VERSION ""

NS_ :

BS_:

BU_: Tester Charger TEL Display BMS VCU MotorController Front_BPS Rear_BPS
VAL_TABLE_ Brightness_Control 10 "100% Brightness" 9 "90% Brightness" 8 "80% Brightness" 7 "70% Brightness" 6 "60% Brightness" 5 "50% Brightness" 4 "40% Brightness" 3 "30% Brightness" 2 "20% Brightness" 1 "10% Brightness" 0 "100% Brightness" ;
VAL_TABLE_ VCU_Charge_Current_Lim_A 7 "FAULT_BIT_READ_SBS_CONFIG" 6 "FAULT_BIT_READ_CALIBRATION" 5 "FAULT_BIT_READ_POWER" 4 "FAULT_BIT_READ_FUEL_GAUGING" 3 "FAULT_BIT_READ_ADV_CHRG_ALGO" 2 "FAULT_BIT_READ_PERM_FAIL" 1 "FAULT_BIT_READ_SETTINGS" 0 "FAULT_BIT_READ_PROTECTION" ;
VAL_TABLE_ Hibernation 2 "Blink" 1 "Enabled" 0 "Disabled" ;
VAL_TABLE_ SpeedMode 3 "Rush" 2 "Ride" 1 "Eco" 0 "Default" ;
VAL_TABLE_ TripStatus 1 "Trip2" 0 "Trip1" ;
VAL_TABLE_ Charger_Status_ERR_NRML 1 "Error" 0 "Normal" ;
VAL_TABLE_ Charger_TX 1 "Disable" 0 "Enable" ;
VAL_TABLE_ Error_State 2 "Permanenet_Fault" 1 "Temporary_Fault" 0 "No Fault" ;
VAL_TABLE_ Kill_SwitchStatus 1 "kill Switch Off" 0 "Kill Switch On" ;
VAL_TABLE_ Switch_statius 1 "Pressed" 0 "Not  Pressed" ;
VAL_TABLE_ Throttle_Control 1 "VCU CAN Command throttle%" 0 "Motor Controller HW Throttle%" ;
VAL_TABLE_ DriveMode_Req 3 "Rush" 2 "Ride" 1 "Eco" 0 "Default" 7 "Reserved" 6 "Reserved" 5 "Reserved" 4 "Reserved" ;
VAL_TABLE_ Deratings 1 "Enabled" 0 "Disabled" ;
VAL_TABLE_ DriveMode_Ack 7 "Reserved" 6 "Reserved" 5 "Reserved" 4 "Reserved" 3 "Rush" 2 "Ride" 1 "Eco" 0 "Reserved" ;
VAL_TABLE_ OCD_Latch 1 "Lacth" 0 "Default" ;
VAL_TABLE_ Load_V_present 1 "DFET On" 0 "DFET Off" ;
VAL_TABLE_ KeyStatus_BMS 1 "Connected" 0 "Not Connected" ;
VAL_TABLE_ DFET_Status 1 "MDFET_ON" 0 "MDFET_OFF" ;
VAL_TABLE_ BMS_Fault_Status 1 "Error" 0 "Normal" ;
VAL_TABLE_ Battery_DFET_Temp_Warning 2 "FET_UNDER_TEMP" 1 "FET_OVER_TEMP" 0 "NO_FET_TEMP_FAULT" ;
VAL_TABLE_ Battery_DFET_TempFault 3 "Reserved" 2 "DFET Under Temperature" 1 "DFET Over Temperature" 0 "No Fault" ;
VAL_TABLE_ Battery_CFET_Temp_Fault 3 "Reserved" 2 "CFET Uder Temperature" 1 "CFET Over Temperature" 0 "No Fault" ;
VAL_TABLE_ CellVoltageFault 3 "Reserved" 2 "Cell Under Votage Fault" 1 "Cell Over Voltage Fault" 0 "No Fault" ;
VAL_TABLE_ Battery_Voltage_fault 3 "Reserved" 2 "Pack Under Voltage Fault" 1 "Pack Over Voltage Fault" 0 "No Fault" ;
VAL_TABLE_ Battery_Thermalrunaway_fault 1 "Fault" 0 "No Fault" ;
VAL_TABLE_ Battery_DischargeTempFault 4 "Charging Under Temperature" 3 "Discharging Under Temperature" 2 "Charging Over Temperature" 1 "Discharging Over Temperature" 0 "No Fault" ;
VAL_TABLE_ Reverse_Enable_Disable 1 "Disable" 0 "Enable" ;
VAL_TABLE_ Charger_LED_Color 3 "Reserved" 2 "Green" 1 "Red" 0 "Disable" ;
VAL_TABLE_ ChargerLEDBlink 15 "na" 14 "na" 13 "na" 12 "na" 11 "na" 10 "na" 9 "na" 8 "na" 7 "na" 6 "na" 5 "na" 4 "blink 4 times" 3 "blink 3 times" 2 "blink 2 times" 1 "blink 1 time" 0 "no blink" ;
VAL_TABLE_ SOH_estimation_flag 7 "NA" 6 "NA" 5 "NA" 4 "NA" 3 "Both flag on" 2 "SOH estimation flag on" 1 "SOH reset trigger on" 0 "Default" ;
VAL_TABLE_ Cell_Upnormal_Voltage 2 "UP_Normal_Min_Voltage_Fault" 1 "UP_Normal_Max_Voltage_Fault" 0 "NO_error" ;
VAL_TABLE_ BMS_State 6 "BMS_Calibration" 5 "BMS_Critical_Fault" 4 "BMS_Charging_Fault" 3 "BMS_Discharging_Fault" 2 "BMS_Charging" 1 "BMS_Discharging" 0 "Idle" ;
VAL_TABLE_ VCU_Trip_status 1 "Trip 2" 0 "Trip 1" ;
VAL_TABLE_ Rare_BPS_Timeout 1 "Rare_BPS_Timeout" 0 "No error" ;
VAL_TABLE_ Front_BPS_TimeOut 2 "reserved" 1 "Front_BPS_Timeout" 0 "No_error" ;
VAL_TABLE_ VehicleModeStatus 6 "Traction disable" 5 "Linphome mode while traction" 4 "Charge" 3 "Traction" 2 "Idle" 1 "Authentication" 0 "Lock" ;
VAL_TABLE_ BootStatus 1 "Boot_opean" 0 "Boot_locked" ;
VAL_TABLE_ ECUErrorCode 326 "Cell Under Voltage Fault" 325 "Cell Over Voltage Fault" 322 "BrakeLamp_Fault" 318 "BMS_CANMSG_Timeout" 315 "Battery_Thermal_Runaway_Fault" 314 "BatteryDisSortCircuitFault" 312 "Charging_under_temp" 310 "Discharging_under_temp" 309 " Charging_over_current_fault" 308 "Discharging_over_current_fault" 307 "Charging_over_temp" 306 "Discharging_over_temp" 305 "DFET under temperature" 304 "DFET over temperature" 303 "CFET under temperature" 302 "CFET over temperature" 301 "Fuse_Fault" 203 "BMS_SCD" 142 "Throttle_2_Low_Voltage" 140 "Motor_Control_Error" 139 "Application_parameters_Fault" 137 "Kill_switch_SRO" 136 "Max_speed_exceeded" 135 "Controller_logic_supply_error" 134 "Throttle channel mismatch " 133 "Motor Stalled" 132 "Throttle SRO" 131 "Contactor_Coil_Overcurrent" 130 "Parameter_Limitation" 129 "Throttle_2_High_Voltage" 128 "High Motor Temperature" 127 "High Controller Temperature" 126 "Corrupted_Position_Sensor_Cal" 125 "Corrupted_Persis_Para" 124 "Corrupted_Comm_Parameters" 123 "Corrupted_Throttle_Calibration" 122 "Corrupted V&I Sensor Calibration" 121 "Motor_Temperature_Sensor" 120 "Controller_Temperature_Sensor" 119 "Motor over temperature" 118 "Controller over temperature" 117 "Charging_Of_Capacitors_Failed" 116 "Throttle 1 Low Voltage" 115 "Throttle 1 High Voltage" 114 "Encoder_Fault" 113 "Throttle_Pedal_Cal_Error" 112 "Corrupted_Application_Parameters" 111 "Contactor_Welded" 110 "Contactor_Bridge_Fault" 109 "Over_Current" 108 "Current_Sensor_Fault" 107 "Sensor_Calibration_Error_V&I" 106 "12V_Failure" 105 "5V_Failure" 104 "Under_Voltage" 103 "Over_Voltage" 102 "Low_Battery_Voltage" 101 "High_Battery_Voltage" ;
VAL_TABLE_ SolenoidFeedbackStatus 1 "solenoid latched" 0 "solenoid unlatched" ;
VAL_TABLE_ RegenFlag 1 "Enable" 0 "Disable" ;
VAL_TABLE_ CalibrationDataSetNumber 4 "Cell 13,14 data" 3 "Cell 10,11,12 data" 2 "Cell 7,8,9 data" 1 "Cell 4,5,6 data" 0 "Cell 1,2,3 data" ;
VAL_TABLE_ CalibrationDescription 171 "Current Mode" 170 "Voltage Mode  " 34 "Current Calibration Third Point" 33 "Voltage Calibration Third Point" 18 "Current Calibration Second Point" 17 "Voltage Calibration Second Point" 2 "Current Calibration First Point" 1 "Voltage Calibration First Point" ;
VAL_TABLE_ CalibrationAckStatus 171 "Current Mode" 170 "Voltage Mode" 17 "Second Voltage point read" 3 "FinalCurrentPointReadCalibrated" 2 "Current point read" 1 "First Voltage point read" ;
VAL_TABLE_ AFESrecWriteStatus 1 "afe_srec written" 0 "afe_srec_not_written" ;
VAL_TABLE_ AFEDataFlashMemoryWriteFaultCode 7 " FAULT_BIT_READ_SBS_CONFIG" 6 "FAULT_BIT_READ_CALIBRATION" 5 "FAULT_BIT_READ_POWER" 4 "FAULT_BIT_READ_FUEL_GAUGING" 3 " FAULT_BIT_READ_ADV_CHRG_ALGO" 2 "FAULT_BIT_READ_PERM_FAIL" 1 "FAULT_BIT_READ_SETTINGS" 0 "FAULT_BIT_READ_PROTECTION" ;
VAL_TABLE_ I2c_Status 517 "STATUS_I2C_BUS_BUSY" 516 "STATUS_I2C_ABORTED" 515 "STATUS_I2C_ARBITRATION_LOST " 514 "STATUS_I2C_RX_OVERRUN " 513 "STATUS_I2C_TX_UNDERRUN" 512 "STATUS_I2C_RECEIVED_NACK " ;
VAL_TABLE_ SystemDiagInitFaultCode 30 "FaultBitReadAFEHistoryFaultData" 29 "FAULTBIT_READ_AFE_LIFE_TIME_DATA" 28 "FAULT_BIT_INT_FLASH_WRITE_FAILED" 27 "FAULT_BIT_INT_FLASH_READ_FAILED" 26 "AULT_BIT_ADC_READ" 25 "FAULT_BIT_AFE_READ " 24 "FAULT_BIT_POST_OS_INIT_FAILED" 23 "FAULT_BIT_OS_CREATE_INTRPTS" 22 "FAULT_BIT_OS_CREATE_TASK" 21 "FAULT_BIT_OS_CREATE_QUEUE" 20 "FAULT_BIT_OS_CREATE_SEMPR" 19 "FAULT_BIT_CAN_TX" 18 "FAULT_BIT_INTERNAL_FLASH_INIT" 17 "FAULT_BIT_I2C_CRC_ERROR" 16 "FAULT_BIT_I2C_RX_ERROR" 15 "FAULT_BIT_I2C_TX_ERROR" 14 "FAULT_BIT_I2C_INIT" 13 "FAULT_BIT_ADC_INIT" 12 "FAULT_BIT_TIMER_FTM1" 11 "FAULT_BIT_TIMER_FTM0" 10 "FAULT_BIT_CAN_INIT_1" 9 "FAULT_BIT_GPIO_INIT" 8 "FAULT_BIT_CLOCK_UPDATE" 7 "FAULT_BIT_BOOT_CLOCK_INIT" 6 "FAULT_BIT_RESET_SOFT" 5 "FAULT_BIT_RESET_NRST_EXT" 4 "FAULT_BIT_RESET_ACK_ERR" 3 "FAULT_BIT_RESET_LV_DETECT" 2 "FAULT_BIT_RESET_SJTAG" 1 "FAULT_BIT_RESET_POWER_ON" 0 "FAULT_BIT_RESET_WDG" ;
VAL_TABLE_ BatteryAFETempWarning 4 "CHARGING_UNDER_TEMP_FAULT" 3 "DISCHARGING_UNDER_TEMPE_FAULT" 2 "CHARGING_OVER_TEMP_FAULT" 1 "DISCHARGING_OVER_TEMPE_FAULT" 0 "NO_TEMP_FAULT" ;
VAL_TABLE_ BatteryMDFETTempWarning 2 "FET_UNDER_TEMP" 1 "FET_OVER_TEMP" 0 "NO_FET_TEMP_FAULT" ;
VAL_TABLE_ BatteryCellVoltageWarning 2 "UNDER_VOLTAGE_FAULT" 1 "OVER_VOLTAGE_FAULT" 0 "NO_VOLTAGE_FAULT" ;
VAL_TABLE_ BatteryCFETTempWarning 2 "CHARG_UNDER_TEMP_FAULT" 1 "CHARG_OVER_TEMP_FAULT" 0 "NO_CHG_TEMP_FAULT" ;
VAL_TABLE_ BatteryTempWarning 4 "CHARGING_UNDER_TEMP_FAULT" 3 "DISCHARGING_UNDER_TEMPE_FAULT" 2 "CHARGING_OVER_TEMP_FAULT" 1 "DISCHARGING_OVER_TEMPE_FAULT" 0 "NO_TEMP_FAULT" ;
VAL_TABLE_ BatteryCurrentWarning 3 "RESERVED" 2 " CHARGING_OVER_CURRENT_FAULT" 1 "DISCHARGING_OVER_CURRENT_FAULT" 0 "NO_CURRENT_FAULT" ;
VAL_TABLE_ ParkArrowBlink 3 "Top and Bottom Arrow Blink" 2 "Top Arrow Blink" 1 "Bottom Arrow Blink" 0 "No Blink" ;
VAL_TABLE_ On_Off 1 "ON" 0 "OFF" ;
VAL_TABLE_ LED_Color 3 "Reserved" 2 "Green" 1 "Red" 0 "Disable" ;
VAL_TABLE_ BatteryChargingTempFault 4 "Reserved" 3 "Reserved" 2 "Charging Under Temperature" 1 "Charging Over Temperature" 0 "No Fault" ;
VAL_TABLE_ BatteryFull 1 "Battery Full" 0 "Default" ;
VAL_TABLE_ Latch 1 "Latch" 0 "Default" ;
VAL_TABLE_ Gauge_TemperatureFault 3 "Reserved" 2 "Gauge UT Fault" 1 "Gauge OT Fault" 0 "Gauge Temperature Normal" ;
VAL_TABLE_ Auth_Fault 1 "Auth Fault" 0 "No Auth Fault" ;
VAL_TABLE_ Fuse 1 "Fuse Blown" 0 "Normal" ;
VAL_TABLE_ Reset_Display 7 "Reserved" 6 "Reserved" 5 "Reserved" 4 "Reserved" 3 "Clear Service Icon" 2 "Reset Trip 2" 1 "Reset Trip1" 0 "Default" ;
VAL_TABLE_ CFET_Status 1 "CFET On" 0 "CFET Off" ;
VAL_TABLE_ Charger_Enable 1 "Disable" 0 "Enable" ;
VAL_TABLE_ DrivenMode 7 "Reserved" 6 "Reserved" 5 "Reserved" 4 "Reserved" 3 "Reserved" 2 "Rush" 1 "Sport" 0 "Ride" ;
VAL_TABLE_ Park_Mode_Direction 1 "Forward" 0 "Reverse" ;
VAL_TABLE_ Park_Mode_Enable 1 "Park Enabled" 0 "Park Disabled" ;
VAL_TABLE_ Version_Req 1 "Update Version" 0 "Default" ;
VAL_TABLE_ VehicleMode 9 "Reserved" 8 "Reserved" 7 "Reserved" 6 "Hibernation" 5 "Cloud Update Mode" 4 "Charging" 3 "Reverse" 2 "Forward" 1 "Idle" 0 "Sleep/Lock" ;
VAL_TABLE_ FET_Fault 3 "Reserved" 2 "Reserved" 1 "Over Temperature " 0 "No Fault" ;
VAL_TABLE_ Precharging_Status 3 "Precharging Failed" 2 "Precharging Successful" 1 "Precharging In-progress" 0 "Default" ;
VAL_TABLE_ Drive_Manoeuvre 4 "Acceleration Backward" 3 "Direction Transition" 2 "Service Braking " 1 "Neutral braking" 0 "Accelartion Forward  " ;
VAL_TABLE_ Motor_ErrorCodes 94 "Kill switch Off" 93 "Kill switch SRO" 83 "Motor stalled " 82 "Throttle SRO" 52 "High motor temperature " 51 "High controller temperature " 97 "Motor control error " 96 "Application parameters fault" 92 "Max. speed exceeded " 90 "Controller logicsupply error " 85 "Throttle channel mismatch " 66 "Contactor coil overcurrent" 56 "Parameter limitation" 54 "Throttle 2 Low Voltage" 53 "Throttle 2 High Voltage" 49 "Corrupted positionsensor cal" 48 "Corrupted Persis Para" 47 "Corrupted Comm parameters \r" 46 "Corrupted throttle calibration" 45 "Corrupted V&I sensor calibration" 44 "Motor temperature sensor" 43 "Controller temperature sensor" 42 "Motor over temperature" 36 "Charging of capacitors failed " 34 "Throttle 1 Low Voltage" 32 "Encoder Fault" 41 "Controller over temperature" 33 "Throttle 1 High Voltage" 31 "Throttle Pedal Cal Error" 26 "Corrupted Application Parameters" 25 "Contactor  Welded" 24 "Contactor Bridge Fault" 21 "Over Current" 18 "Current Sensor Fault" 17 "Sensor Calibration Error V&I" 16 "12V Failure" 15 "5V Failure" 14 "Under Voltage V<32" 13 "Over Voltage V>62" 12 "Low Battery Voltage V<28" 11 "High Battery Voltage V>100" ;
VAL_TABLE_ Am_Pm 1 "pm" 0 "am" ;
VAL_TABLE_ Blink 1 "Blinking" 0 "No Blinking" ;
VAL_TABLE_ Trip 1 "Trip 2" 0 "Trip 1" ;
VAL_TABLE_ Enable_Disable 1 "Enabled" 0 "Disabled" ;
VAL_TABLE_ Direction 3 "Reserved" 2 "Reverse" 1 "Forward" 0 "Neutral" ;
VAL_TABLE_ KillSwitch 1 "Kill Switch Off" 0 "Kill Switch On" ;
VAL_TABLE_ PowerStage 3 "Not Used" 2 "On" 1 "Active Short" 0 "Off" ;
VAL_TABLE_ MotorMode 7 "Reserved" 6 "Reserved" 5 "Reserved" 4 "Reserved" 3 "Rush" 2 "Ride" 1 "Eco" 0 "Reserved" ;
VAL_TABLE_ BrakeStatus 1 "Pressed" 0 "Not Pressed" ;
VAL_TABLE_ SideStandStatus 1 "Up" 0 "Down" ;
VAL_TABLE_ ServiceIndication 1 "Enable" 0 "Disable" ;
VAL_TABLE_ ChargePlugStatus 1 "Connected" 0 "Not Connected" ;
VAL_TABLE_ RegenStatus 1 "Enabled" 0 "Disabled" ;
VAL_TABLE_ VCU_DisplayMode 9 "Reserved" 8 "Reserved" 7 "Reserved" 6 "Factory Mode" 5 "Charging" 4 "Park Forward" 3 "Park Reverse" 2 "Forward" 1 "Idle" 0 "Sleep" ;
VAL_TABLE_ Green_Red 3 "Green&Red" 2 "Red" 1 "Green" 0 "Default" ;
VAL_TABLE_ CurrentFaults 3 "Reserved" 2 "Charging Over Current Fault" 1 "Discharging Over Current Fault" 0 "No Fault" ;
VAL_TABLE_ VoltageFaults 3 "Reserved " 2 "Under Voltage Fault" 1 "Over Voltage Fault" 0 "No Fault" ;
VAL_TABLE_ BatteryDischargingTempFault 4 "Reserved" 3 "Reserved" 2 "Discharging Under Temperature" 1 "Discharging Over Temperature" 0 "No Fault" ;
VAL_TABLE_ Fault 1 "Fault" 0 "No Fault" ;
VAL_TABLE_ Authentication 3 "Fail" 2 "Pass" 1 "InProgress" 0 "Default" ;
VAL_TABLE_ BalancingStatus 1 "Balancing" 0 "Not Balancing" ;
VAL_TABLE_ BMS_Status 10 "Reserved" 9 "Reserved" 8 "Reserved" 7 "Charge Recovery Fault" 6 "Discharge Recovery Fault" 5 "Critical Fault" 4 "Hibernate" 3 "Charging" 2 "Discharging" 1 "Precharging" 0 "Sleep" ;
VAL_TABLE_ charger_status_msg 1 "Error" 0 "Normal" ;
VAL_TABLE_ SECURITY_Mode_OP_sts 3 "Sealed" 2 "Unsealed" 1 "Full_Access" 0 "Reserved" ;
VAL_TABLE_ Error_Code_BT_Sts 7 "Unknown_Error" 6 "Bad_Size" 5 "Overflow/UnderFlow" 4 "AccessDenied" 3 "unsupported_Command" 2 "Reserved_Command" 1 "Busy" 0 "OK" ;

BO_ 3221225472 VECTOR__INDEPENDENT_SIG_MSG: 0 Vector__XXX
 SG_ subversion_u8 : 0|8@1+ (1,0) [0|255] "" Vector__XXX

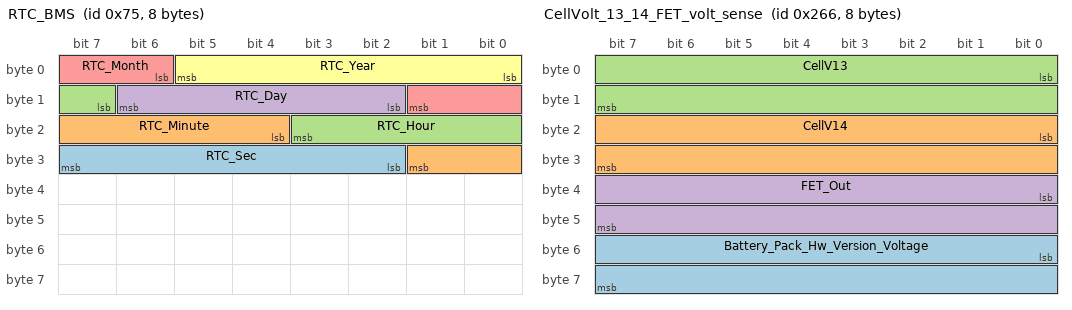
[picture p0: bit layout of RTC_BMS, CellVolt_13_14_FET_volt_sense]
BO_ 117 RTC_BMS: 8 BMS
 SG_ RTC_Sec : 26|6@1+ (1,0) [0|63] ""  VCU
 SG_ RTC_Minute : 20|6@1+ (1,0) [0|63] ""  VCU
 SG_ RTC_Hour : 15|5@1+ (1,0) [0|31] ""  VCU
 SG_ RTC_Day : 10|5@1+ (1,0) [0|31] ""  VCU
 SG_ RTC_Month : 6|4@1+ (1,0) [0|15] ""  VCU
 SG_ RTC_Year : 0|6@1+ (1,0) [0|63] ""  VCU

BO_ 614 CellVolt_13_14_FET_volt_sense: 8 BMS
 SG_ Battery_Pack_Hw_Version_Voltage : 48|16@1+ (0.01,0) [0|655.35] "" Vector__XXX
 SG_ CellV14 : 16|16@1+ (0.001,0) [0|655.35] "V" Vector__XXX
 SG_ CellV13 : 0|16@1+ (0.001,0) [0|65.535] "V" Vector__XXX
 SG_ FET_Out : 32|16@1+ (0.01,0) [0|65.535] "V"  VCU,TEL

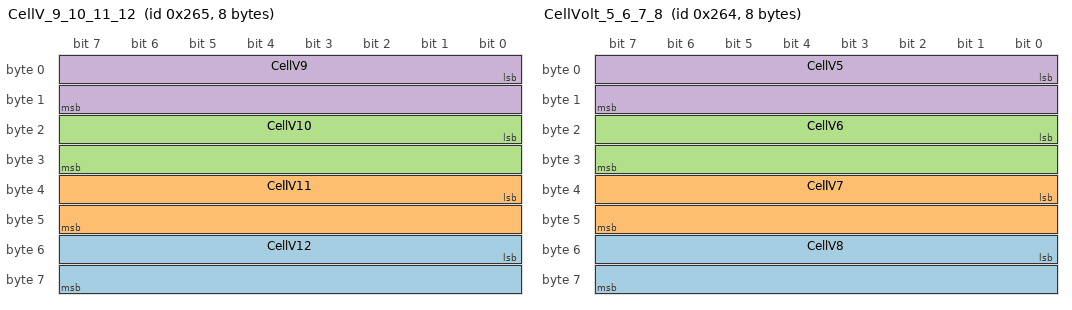
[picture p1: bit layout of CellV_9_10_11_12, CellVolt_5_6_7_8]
BO_ 613 CellV_9_10_11_12: 8 BMS
 SG_ CellV12 : 48|16@1+ (0.001,0) [0|65.535] ""  VCU,TEL
 SG_ CellV11 : 32|16@1+ (0.001,0) [0|65.535] ""  VCU,TEL
 SG_ CellV10 : 16|16@1+ (0.001,0) [0|65.535] ""  VCU,TEL
 SG_ CellV9 : 0|16@1+ (0.001,0) [0|65.535] ""  VCU,TEL

BO_ 612 CellVolt_5_6_7_8: 8 BMS
 SG_ CellV8 : 48|16@1+ (0.001,0) [0|65.535] ""  VCU,TEL
 SG_ CellV7 : 32|16@1+ (0.001,0) [0|65.535] "V"  VCU,TEL
 SG_ CellV6 : 16|16@1+ (0.001,0) [0|65.535] ""  VCU,TEL
 SG_ CellV5 : 0|16@1+ (0.001,0) [0|65.535] ""  VCU,TEL

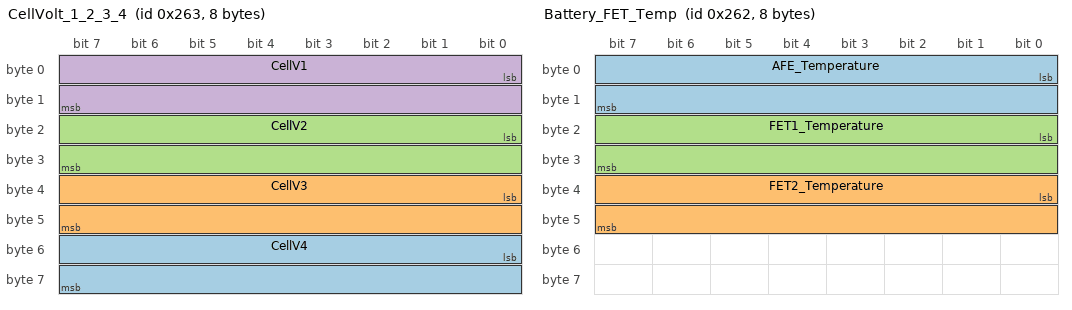
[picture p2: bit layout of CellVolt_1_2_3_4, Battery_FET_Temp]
BO_ 611 CellVolt_1_2_3_4: 8 BMS
 SG_ CellV4 : 48|16@1+ (0.001,0) [0|65.535] ""  VCU,TEL
 SG_ CellV3 : 32|16@1+ (0.001,0) [0|65.535] ""  VCU,TEL
 SG_ CellV2 : 16|16@1+ (0.001,0) [0|65.535] ""  VCU,TEL
 SG_ CellV1 : 0|16@1+ (0.001,0) [0|65.535] "V"  VCU,TEL

BO_ 610 Battery_FET_Temp: 8 BMS
 SG_ AFE_Temperature : 0|16@1- (0.1,0) [-327.68|327.67] "" Vector__XXX
 SG_ FET2_Temperature : 32|16@1- (0.01,0) [-327.68|327.67] "degC"  VCU,TEL
 SG_ FET1_Temperature : 16|16@1- (0.01,0) [-327.68|327.67] "degC"  VCU,TEL

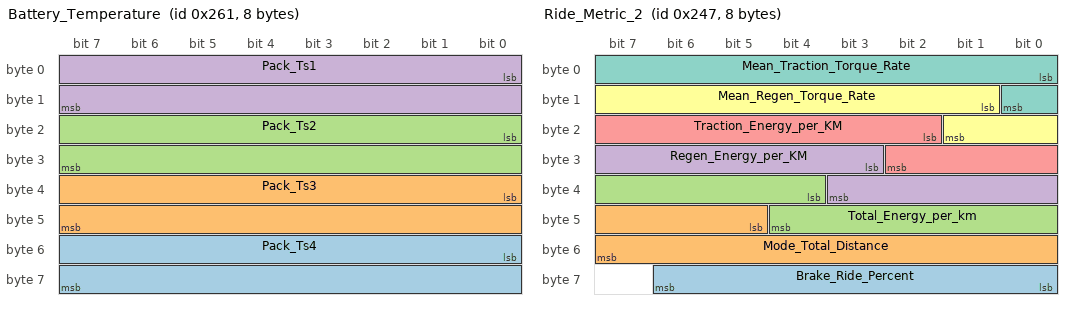
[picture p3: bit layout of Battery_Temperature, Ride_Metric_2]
BO_ 609 Battery_Temperature: 8 BMS
 SG_ Pack_Ts4 : 48|16@1- (0.01,0) [-327.68|327.67] "degC"  VCU,TEL
 SG_ Pack_Ts3 : 32|16@1- (0.01,0) [-327.68|327.67] "degC"  VCU,TEL
 SG_ Pack_Ts2 : 16|16@1- (0.01,0) [-3276.8|3276.7] "degC"  VCU,TEL
 SG_ Pack_Ts1 : 0|16@1- (0.01,0) [-327.68|327.67] "degC"  VCU,TEL

BO_ 583 Ride_Metric_2: 8 VCU
 SG_ Brake_Ride_Percent : 56|7@1+ (1,0) [0|127] ""  TEL
 SG_ Mode_Total_Distance : 45|11@1+ (0.1,0) [0|204.7] ""  TEL
 SG_ Total_Energy_per_km : 36|9@1+ (0.1,0) [0|51.1] ""  TEL
 SG_ Regen_Energy_per_KM : 27|9@1+ (0.1,0) [0|51.1] ""  TEL
 SG_ Traction_Energy_per_KM : 18|9@1+ (0.1,0) [0|51.1] ""  TEL
 SG_ Mean_Regen_Torque_Rate : 9|9@1+ (1,0) [0|511] ""  TEL
 SG_ Mean_Traction_Torque_Rate : 0|9@1+ (1,0) [0|511] ""  TEL

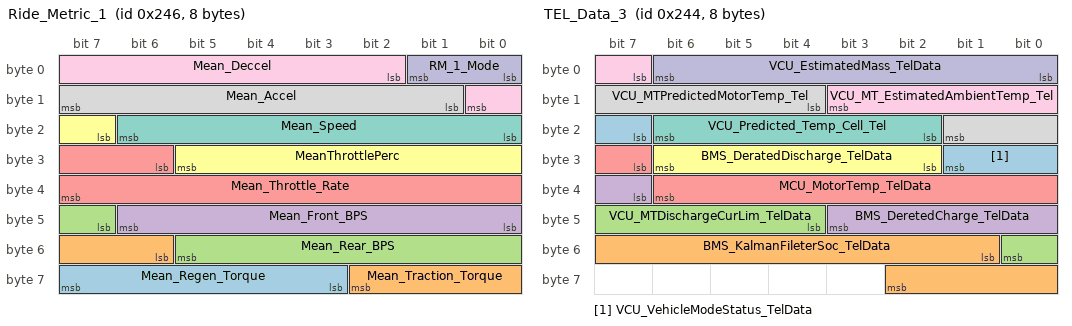
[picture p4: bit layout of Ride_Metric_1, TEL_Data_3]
BO_ 582 Ride_Metric_1: 8 VCU
 SG_ Mean_Regen_Torque : 59|5@1+ (1,0) [0|31] ""  TEL
 SG_ Mean_Traction_Torque : 54|5@1+ (1,0) [0|31] ""  TEL
 SG_ Mean_Rear_BPS : 47|7@1+ (1,0) [0|127] ""  TEL
 SG_ Mean_Front_BPS : 40|7@1+ (1,0) [0|127] ""  TEL
 SG_ Mean_Throttle_Rate : 30|10@1+ (1,0) [0|1023] ""  TEL
 SG_ MeanThrottlePerc : 23|7@1+ (1,0) [0|127] ""  TEL
 SG_ Mean_Speed : 16|7@1+ (1,0) [0|127] ""  TEL
 SG_ Mean_Accel : 9|7@1+ (0.1,0) [0|12.7] ""  TEL
 SG_ Mean_Deccel : 2|7@1+ (0.1,0) [0|12.7] ""  TEL
 SG_ RM_1_Mode : 0|2@1+ (1,0) [0|3] ""  TEL

BO_ 580 TEL_Data_3: 8 VCU
 SG_ VCU_VehicleModeStatus_TelData : 23|3@1+ (1,0) [0|7] ""  TEL
 SG_ BMS_KalmanFileterSoc_TelData : 49|10@1+ (0.1,0) [0|102.3] "%"  TEL
 SG_ VCU_MTDischargeCurLim_TelData : 44|5@1+ (5,0) [0|155] "A"  TEL
 SG_ BMS_DeretedCharge_TelData : 39|5@1+ (5,0) [0|155] "A"  TEL
 SG_ MCU_MotorTemp_TelData : 31|8@1+ (1,-40) [-40|215] ""  TEL
 SG_ BMS_DeratedDischarge_TelData : 26|5@1+ (5,0) [0|155] ""  TEL
 SG_ VCU_Predicted_Temp_Cell_Tel : 18|5@1+ (3,0) [0|93] ""  TEL
 SG_ VCU_MTPredictedMotorTemp_Tel : 12|6@1+ (3,0) [0|189] ""  TEL
 SG_ VCU_MT_EstimatedAmbientTemp_Tel : 7|5@1+ (2,0) [0|62] ""  TEL
 SG_ VCU_EstimatedMass_TelData : 0|7@1+ (5,100) [100|735] ""  TEL

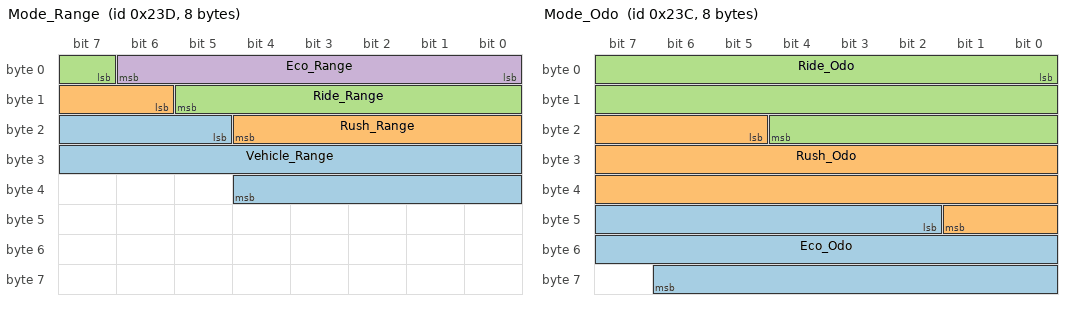
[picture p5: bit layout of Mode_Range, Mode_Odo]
BO_ 573 Mode_Range: 8 VCU
 SG_ Vehicle_Range : 21|16@1+ (0.1,0) [0|6553.5] ""  Tester
 SG_ Rush_Range : 14|7@1+ (1,0) [0|127] ""  Tester
 SG_ Ride_Range : 7|7@1+ (1,0) [0|127] ""  Tester
 SG_ Eco_Range : 0|7@1+ (1,0) [0|127] ""  Tester

BO_ 572 Mode_Odo: 8 VCU
 SG_ Eco_Odo : 42|21@1+ (0.1,0) [0|209715.1] "Km"  TEL
 SG_ Rush_Odo : 21|21@1+ (0.1,0) [0|209715.1] "Km"  TEL
 SG_ Ride_Odo : 0|21@1+ (0.1,0) [0|209715.1] "Km"  TEL

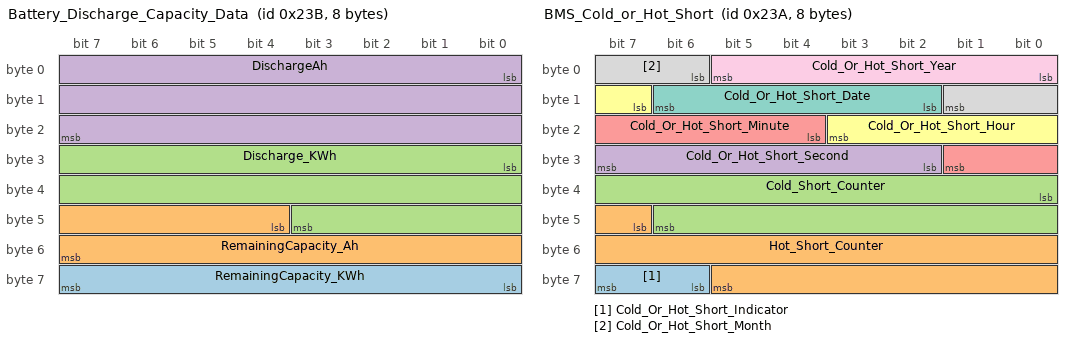
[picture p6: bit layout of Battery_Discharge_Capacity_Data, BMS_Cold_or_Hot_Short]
BO_ 571 Battery_Discharge_Capacity_Data: 8 BMS
 SG_ RemainingCapacity_KWh : 56|8@1+ (0.1,0) [0|25.5] "Wh" Vector__XXX
 SG_ RemainingCapacity_Ah : 44|12@1+ (0.1,0) [0|409.5] "" Vector__XXX
 SG_ Discharge_KWh : 24|20@1+ (0.1,0) [0|104857.5] ""  TEL
 SG_ DischargeAh : 0|24@1+ (0.1,0) [0|1677721.5] "Ah"  TEL

BO_ 570 BMS_Cold_or_Hot_Short: 8 BMS
 SG_ Cold_Or_Hot_Short_Indicator : 62|2@1+ (1,0) [0|3] "" Vector__XXX
 SG_ Hot_Short_Counter : 47|15@1+ (1,0) [0|32767] ""  VCU
 SG_ Cold_Short_Counter : 32|15@1+ (1,0) [0|32767] ""  VCU
 SG_ Cold_Or_Hot_Short_Second : 26|6@1- (1,0) [0|0] ""  VCU
 SG_ Cold_Or_Hot_Short_Minute : 20|6@1+ (1,0) [0|63] ""  VCU
 SG_ Cold_Or_Hot_Short_Hour : 15|5@1+ (1,0) [0|31] ""  VCU
 SG_ Cold_Or_Hot_Short_Date : 10|5@1+ (1,0) [0|31] ""  VCU
 SG_ Cold_Or_Hot_Short_Month : 6|4@1+ (1,0) [0|15] ""  VCU
 SG_ Cold_Or_Hot_Short_Year : 0|6@1+ (1,0) [0|63] ""  VCU

BO_ 569 Cell_BalancingStatus: 8 BMS
 SG_ vcc_aux_failure_counter : 48|8@1+ (1,0) [0|255] "" Vector__XXX
 SG_ shunt_res_temperature : 32|16@1- (0.01,0) [-327.68|327.67] "" Vector__XXX
 SG_ battery_pack_ambient_temperature : 16|16@1- (0.01,0) [-327.68|327.67] "" Vector__XXX
 SG_ Cell_14_BalancingStatus : 13|1@1+ (1,0) [0|1] ""  TEL
 SG_ Cell_13_BalancingStatus : 12|1@1+ (1,0) [0|1] ""  TEL
 SG_ Cell_12_BalancingStatus : 11|1@1+ (1,0) [0|1] ""  TEL
 SG_ Cell_11_BalancingStatus : 10|1@1+ (1,0) [0|1] ""  TEL
 SG_ Cell_10_BalancingStatus : 9|1@1+ (1,0) [0|1] ""  TEL
 SG_ Cell_9_BalancingStatus : 8|1@1+ (1,0) [0|1] ""  TEL
 SG_ Cell_8_BalancingStatus : 7|1@1+ (1,0) [0|1] ""  TEL
 SG_ Cell_7_BalancingStatus : 6|1@1+ (1,0) [0|1] ""  TEL
 SG_ Cell_6_BalancingStatus : 5|1@1+ (1,0) [0|1] ""  TEL
 SG_ Cell_5_BalancingStatus : 4|1@1+ (1,0) [0|1] ""  TEL
 SG_ Cell_4_BalancingStatus : 3|1@1+ (1,0) [0|1] ""  TEL
 SG_ Cell_3_BalancingStatus : 2|1@1+ (1,0) [0|1] ""  TEL
 SG_ Cell_2_BalancingStatus : 1|1@1+ (1,0) [0|1] ""  TEL
 SG_ Cell_1_BalancingStatus : 0|1@1+ (1,0) [0|0] ""  TEL

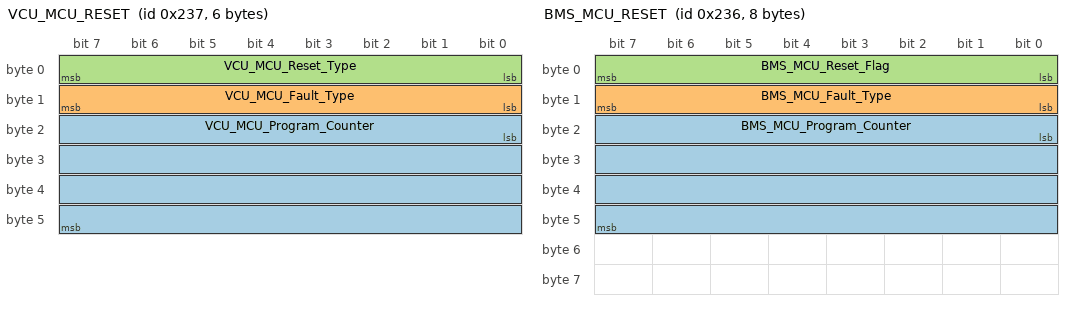
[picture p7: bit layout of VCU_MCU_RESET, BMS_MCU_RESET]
BO_ 567 VCU_MCU_RESET: 6 VCU
 SG_ VCU_MCU_Program_Counter : 16|32@1+ (1,0) [0|4294967295] ""  TEL
 SG_ VCU_MCU_Fault_Type : 8|8@1+ (1,0) [0|255] ""  TEL
 SG_ VCU_MCU_Reset_Type : 0|8@1+ (1,0) [0|255] ""  TEL

BO_ 566 BMS_MCU_RESET: 8 BMS
 SG_ BMS_MCU_Program_Counter : 16|32@1+ (1,0) [0|4294967295] ""  Tester
 SG_ BMS_MCU_Fault_Type : 8|8@1+ (1,0) [0|255] ""  Tester
 SG_ BMS_MCU_Reset_Flag : 0|8@1+ (1,0) [0|255] ""  Tester

BO_ 563 VCU_Display_Info3: 8 VCU
 SG_ Side_stand_blink : 56|1@1+ (1,0) [0|255] "" Vector__XXX
 SG_ Brightness_control : 52|4@1+ (1,0) [0|15] "%" Vector__XXX
 SG_ Selected_Trip_Status : 51|1@1+ (1,0) [0|1] ""  Display,TEL
 SG_ ParkArrowBlink : 49|2@1+ (1,0) [0|3] ""  Display,TEL
 SG_ Trip1_Blink : 48|1@1+ (1,0) [0|255] ""  Display,TEL
 SG_ Trip2_Blink : 47|1@1+ (1,0) [0|1] ""  Display,TEL
 SG_ PowerBar : 27|20@1+ (1,0) [0|1048575] ""  Display,TEL
 SG_ Reset : 24|3@1+ (1,0) [0|7] ""  Display,TEL
 SG_ Odo_Reset : 23|1@1+ (1,0) [0|1] ""  Display,TEL
 SG_ Service_Blink : 22|1@1+ (1,0) [0|1] ""  Display,TEL
 SG_ Hibernation : 19|2@1+ (1,0) [0|3] ""  Display,TEL
 SG_ SpeedMode : 17|2@1+ (1,0) [0|0] ""  Display,TEL
 SG_ ParkBlink : 16|1@1+ (1,0) [0|1] ""  Display,TEL
 SG_ Time_Minutes : 8|8@1+ (1,0) [0|255] ""  Display,TEL
 SG_ Am_Pm : 7|1@1+ (1,0) [0|1] ""  Display,TEL
 SG_ Time_Hours : 3|4@1+ (1,0) [0|15] ""  Display,TEL
 SG_ Mode_Blink : 2|1@1+ (1,0) [0|1] ""  Display,TEL
 SG_ SOC_Blink : 1|1@1+ (1,0) [0|1] ""  Display,TEL
 SG_ Speed_Blink : 0|1@1+ (1,0) [0|1] ""  Display,TEL

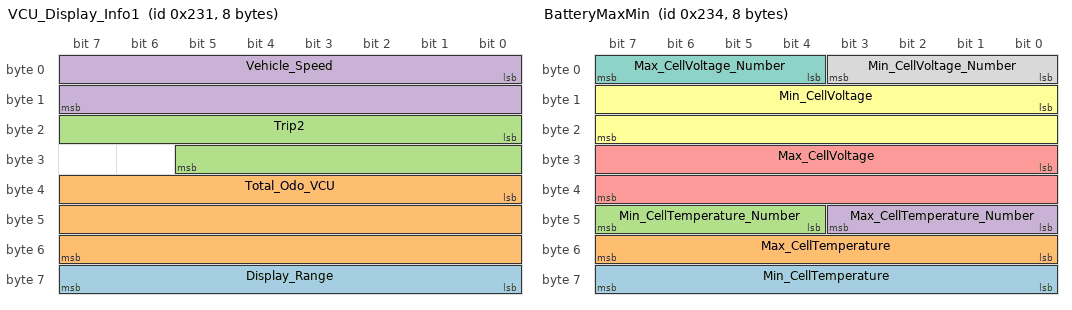
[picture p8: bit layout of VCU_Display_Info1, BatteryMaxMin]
BO_ 561 VCU_Display_Info1: 8 VCU
 SG_ Display_Range : 56|8@1+ (1,0) [0|255] ""  TEL,Display
 SG_ Total_Odo_VCU : 32|24@1+ (0.1,0) [0|1677721.5] "Km"  TEL,Display
 SG_ Trip2 : 16|14@1+ (0.1,0) [0|1638.3] "Km"  TEL,Display
 SG_ Vehicle_Speed : 0|16@1+ (0.01,0) [0|655.35] "Kph"  TEL,Display

BO_ 564 BatteryMaxMin: 8 BMS
 SG_ Min_CellTemperature : 56|8@1- (1,0) [-128|127] ""  TEL
 SG_ Max_CellTemperature : 48|8@1- (1,0) [-128|127] ""  TEL
 SG_ Min_CellTemperature_Number : 44|4@1+ (1,0) [0|15] ""  TEL
 SG_ Max_CellTemperature_Number : 40|4@1+ (1,0) [0|15] ""  TEL
 SG_ Max_CellVoltage : 24|16@1+ (0.001,0) [0|65.535] ""  TEL
 SG_ Min_CellVoltage : 8|16@1+ (0.001,0) [0|65.535] ""  TEL
 SG_ Max_CellVoltage_Number : 4|4@1+ (1,0) [0|15] ""  TEL
 SG_ Min_CellVoltage_Number : 0|4@1+ (1,0) [0|15] ""  TEL

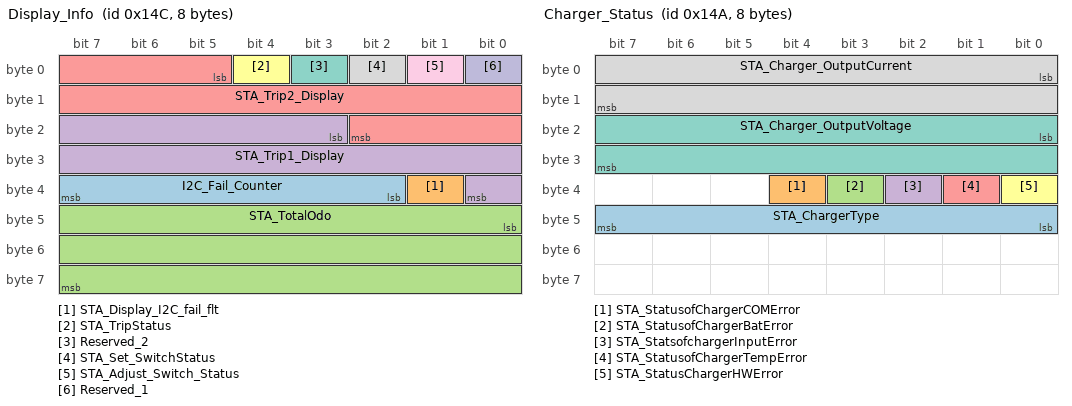
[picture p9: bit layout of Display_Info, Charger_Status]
BO_ 332 Display_Info: 8 Display
 SG_ I2C_Fail_Counter : 34|6@1+ (1,0) [0|63] "" Vector__XXX
 SG_ STA_Display_I2C_fail_flt : 33|1@1+ (1,0) [0|1] "" Vector__XXX
 SG_ STA_TotalOdo : 40|24@1+ (0.1,0) [0|1677721.5] "Km"  TEL,VCU
 SG_ STA_Trip1_Display : 19|14@1+ (0.1,0) [0|1638.3] "Km"  TEL,VCU
 SG_ STA_Trip2_Display : 5|14@1+ (0.1,0) [0|1638.3] "Km"  TEL,VCU
 SG_ STA_TripStatus : 4|1@1+ (1,0) [0|1] ""  TEL,VCU
 SG_ Reserved_2 : 3|1@1+ (1,0) [0|1] ""  TEL,VCU
 SG_ STA_Set_SwitchStatus : 2|1@1+ (1,0) [0|1] ""  TEL,VCU
 SG_ STA_Adjust_Switch_Status : 1|1@1+ (1,0) [0|1] ""  TEL,VCU
 SG_ Reserved_1 : 0|1@1+ (1,0) [0|1] ""  TEL,VCU

BO_ 330 Charger_Status: 8 Charger
 SG_ STA_ChargerType : 40|8@1+ (1,0) [0|255] ""  TEL,BMS,VCU
 SG_ STA_StatusofChargerCOMError : 36|1@1+ (1,0) [0|1] ""  TEL,BMS,VCU
 SG_ STA_StatusofChargerBatError : 35|1@1+ (1,0) [0|1] ""  TEL,BMS,VCU
 SG_ STA_StatsofchargerInputError : 34|1@1+ (1,0) [0|1] ""  TEL,BMS,VCU
 SG_ STA_StatusofChargerTempError : 33|1@1+ (1,0) [0|1] ""  TEL,BMS,VCU
 SG_ STA_StatusChargerHWError : 32|1@1+ (1,0) [0|1] ""  TEL,BMS,VCU
 SG_ STA_Charger_OutputVoltage : 16|16@1+ (0.01,0) [0|655.35] ""  TEL,BMS,VCU
 SG_ STA_Charger_OutputCurrent : 0|16@1+ (0.1,0) [0|6553.5] ""  TEL,BMS,VCU

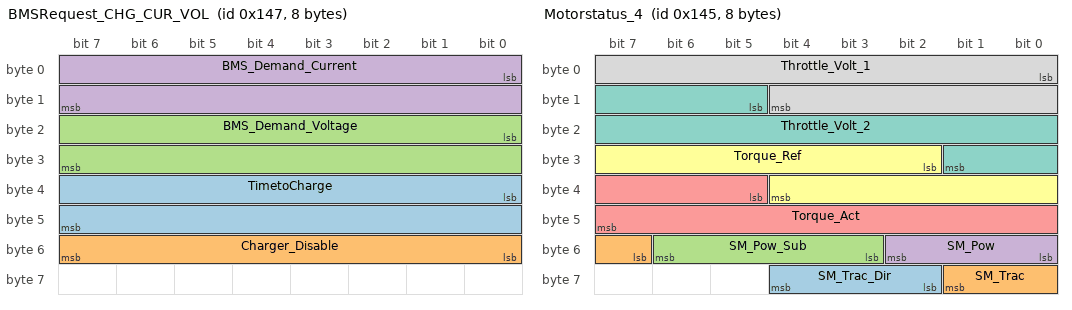
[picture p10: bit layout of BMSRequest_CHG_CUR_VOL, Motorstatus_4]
BO_ 327 BMSRequest_CHG_CUR_VOL: 8 BMS
 SG_ TimetoCharge : 32|16@1+ (1,0) [0|65535] "" Vector__XXX
 SG_ Charger_Disable : 48|8@1+ (1,0) [0|255] ""  TEL,Charger
 SG_ BMS_Demand_Voltage : 16|16@1+ (0.01,0) [0|655.35] ""  TEL,Charger
 SG_ BMS_Demand_Current : 0|16@1+ (0.1,0) [0|6553.5] ""  TEL,Charger

BO_ 325 Motorstatus_4: 8 MotorController
 SG_ SM_Trac_Dir : 58|3@1+ (1,0) [0|7] ""  Tester,TEL
 SG_ SM_Trac : 55|3@1+ (1,0) [0|7] ""  Tester,TEL
 SG_ SM_Pow_Sub : 51|4@1+ (1,0) [0|15] ""  Tester,TEL
 SG_ SM_Pow : 48|3@1+ (1,0) [0|7] ""  Tester,TEL
 SG_ Torque_Act : 37|11@1- (0.1,0) [-102.4|102.3] ""  Tester,TEL
 SG_ Torque_Ref : 26|11@1- (0.1,0) [-102.4|102.3] "Nm"  Tester,TEL
 SG_ Throttle_Volt_2 : 13|13@1+ (1,0) [0|8191] ""  Tester,TEL
 SG_ Throttle_Volt_1 : 0|13@1+ (1,0) [0|8191] "mV"  Tester,TEL

BO_ 70 BMS_SYSTEM_FAILURE: 8 BMS
 SG_ FLT_System_Dig_init_FaultCode : 0|32@1+ (1,0) [0|4294967295] ""  VCU

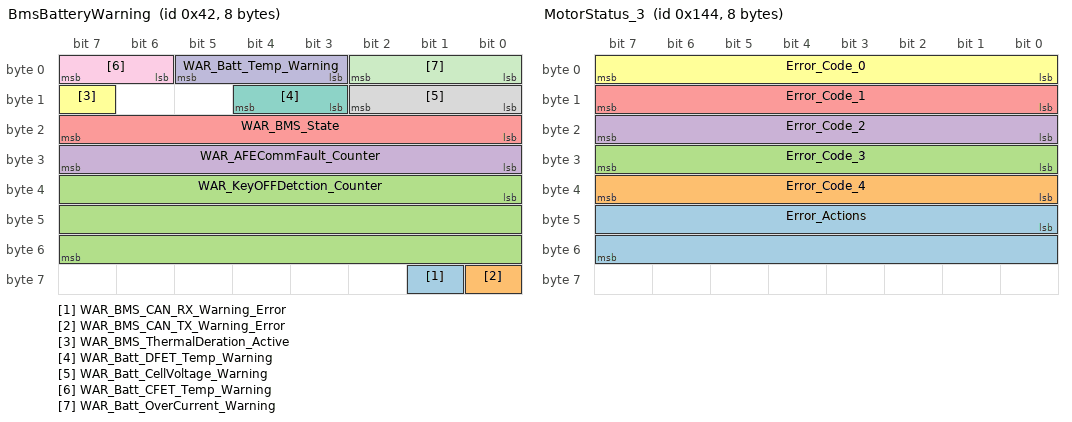
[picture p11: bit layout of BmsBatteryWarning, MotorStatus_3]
BO_ 66 BmsBatteryWarning: 8 BMS
 SG_ WAR_BMS_CAN_RX_Warning_Error : 57|1@1+ (1,0) [0|1] "" Vector__XXX
 SG_ WAR_BMS_CAN_TX_Warning_Error : 56|1@1+ (1,0) [0|1] "" Vector__XXX
 SG_ WAR_KeyOFFDetction_Counter : 32|24@1+ (1,0) [0|4294967295] ""  VCU
 SG_ WAR_AFECommFault_Counter : 24|8@1+ (1,0) [0|255] ""  VCU
 SG_ WAR_BMS_State : 16|8@1+ (1,0) [0|255] ""  VCU
 SG_ WAR_BMS_ThermalDeration_Active : 15|1@1+ (1,0) [0|1] ""  VCU
 SG_ WAR_Batt_DFET_Temp_Warning : 11|2@1+ (1,0) [0|3] ""  VCU
 SG_ WAR_Batt_CellVoltage_Warning : 8|3@1+ (1,0) [0|7] ""  VCU
 SG_ WAR_Batt_CFET_Temp_Warning : 6|2@1+ (1,0) [0|3] ""  VCU
 SG_ WAR_Batt_Temp_Warning : 3|3@1+ (1,0) [0|7] ""  VCU
 SG_ WAR_Batt_OverCurrent_Warning : 0|3@1+ (1,0) [0|7] ""  VCU

BO_ 324 MotorStatus_3: 8 MotorController
 SG_ Error_Actions : 40|16@1+ (1,0) [0|65535] ""  VCU,TEL
 SG_ Error_Code_4 : 32|8@1+ (1,0) [0|255] ""  VCU,TEL
 SG_ Error_Code_3 : 24|8@1+ (1,0) [0|255] ""  VCU,TEL
 SG_ Error_Code_2 : 16|8@1+ (1,0) [0|255] ""  VCU,TEL
 SG_ Error_Code_1 : 8|8@1+ (1,0) [0|255] ""  VCU,TEL
 SG_ Error_Code_0 : 0|8@1+ (1,0) [0|255] ""  VCU,TEL

CM_ BO_ 3221225472 "This is a message for not used signals, created by Vector CANdb++ DBC OLE DB Provider.";
BA_DEF_ SG_  "SigType" ENUM  "Default","Range","RangeSigned","ASCII","Discrete","Control","ReferencePGN","DTC","StringDelimiter","StringLength","StringLengthControl","MessageCounter","MessageChecksum";
BA_DEF_ BO_  "GenMsgRequestable" INT 0 1;
BA_DEF_ BO_  "GenMsgSendType" ENUM  "Fixed Periodic","Event","Event Periodic";
BA_DEF_ BO_  "GenMsgCycleTime" INT 0 1000000;
BA_DEF_  "ProtocolType" STRING ;
BA_DEF_  "DBName" STRING ;
BA_DEF_  "BusType" STRING ;
BA_DEF_DEF_  "SigType" "Default";
BA_DEF_DEF_  "GenMsgRequestable" 1;
BA_DEF_DEF_  "GenMsgSendType" "Fixed Periodic";
BA_DEF_DEF_  "GenMsgCycleTime" 0;
BA_DEF_DEF_  "ProtocolType" "CAN Standard";
BA_DEF_DEF_  "DBName" "";
BA_DEF_DEF_  "BusType" "CAN";
BA_ "DBName" "RX1_VehicleGEN2_500K_DBC";
BA_ "GenMsgCycleTime" BO_ 117 1000;
BA_ "GenMsgCycleTime" BO_ 614 1000;
BA_ "GenMsgCycleTime" BO_ 612 1000;
BA_ "GenMsgCycleTime" BO_ 611 1000;
BA_ "GenMsgCycleTime" BO_ 610 1000;
BA_ "GenMsgCycleTime" BO_ 609 1000;
BA_ "GenMsgCycleTime" BO_ 580 15000;
BA_ "GenMsgCycleTime" BO_ 573 1000;
BA_ "GenMsgCycleTime" BO_ 572 1000;
BA_ "GenMsgCycleTime" BO_ 571 1000;
BA_ "GenMsgCycleTime" BO_ 570 1000;
BA_ "GenMsgCycleTime" BO_ 569 1000;
BA_ "GenMsgCycleTime" BO_ 567 1000;
BA_ "GenMsgCycleTime" BO_ 566 1000;
BA_ "GenMsgCycleTime" BO_ 563 100;
BA_ "GenMsgCycleTime" BO_ 561 100;
BA_ "GenMsgCycleTime" BO_ 564 250;
BA_ "GenMsgCycleTime" BO_ 332 200;
BA_ "GenMsgCycleTime" BO_ 330 1000;
BA_ "GenMsgCycleTime" BO_ 327 200;
BA_ "GenMsgCycleTime" BO_ 325 100;
BA_ "GenMsgCycleTime" BO_ 70 50;
BA_ "GenMsgCycleTime" BO_ 66 50;
BA_ "GenMsgCycleTime" BO_ 324 10;
VAL_ 580 VCU_VehicleModeStatus_TelData 6 "Traction disable" 5 "Linphome mode while traction" 4 "Charge" 3 "Traction" 2 "Idle" 1 "Authentication" 0 "Lock" ;
VAL_ 569 Cell_14_BalancingStatus 1 "Balancing" 0 "Not Balancing" ;
VAL_ 569 Cell_13_BalancingStatus 1 "Balancing" 0 "Not Balancing" ;
VAL_ 569 Cell_12_BalancingStatus 1 "Balancing" 0 "Not Balancing" ;
VAL_ 569 Cell_11_BalancingStatus 1 "Balancing" 0 "Not Balancing" ;
VAL_ 569 Cell_10_BalancingStatus 1 "Balancing" 0 "Not Balancing" ;
VAL_ 569 Cell_9_BalancingStatus 1 "Balancing" 0 "Not Balancing" ;
VAL_ 569 Cell_8_BalancingStatus 1 "Balancing" 0 "Not Balancing" ;
VAL_ 569 Cell_7_BalancingStatus 1 "Balancing" 0 "Not Balancing" ;
VAL_ 569 Cell_6_BalancingStatus 1 "Balancing" 0 "Not Balancing" ;
VAL_ 569 Cell_5_BalancingStatus 1 "Balancing" 0 "Not Balancing" ;
VAL_ 569 Cell_4_BalancingStatus 1 "Balancing" 0 "Not Balancing" ;
VAL_ 569 Cell_3_BalancingStatus 1 "Balancing" 0 "Not Balancing" ;
VAL_ 569 Cell_2_BalancingStatus 1 "Balancing" 0 "Not Balancing" ;
VAL_ 569 Cell_1_BalancingStatus 1 "Balancing" 0 "Not Balancing" ;
VAL_ 563 Brightness_control 10 "100% Brightness" 9 "90% Brightness" 8 "80% Brightness" 7 "70% Brightness" 6 "60% Brightness" 5 "50% Brightness" 4 "40% Brightness" 3 "30% Brightness" 2 "20% Brightness" 1 "10% Brightness" 0 "100% Brightness" ;
VAL_ 563 Selected_Trip_Status 1 "Trip2" 0 "Trip1" ;
VAL_ 563 ParkArrowBlink 3 "Top and Bottom Arrow Blink" 2 "Top Arrow Blink" 1 "Bottom Arrow Blink" 0 "No Blink" ;
VAL_ 563 Trip1_Blink 1 "Blinking" 0 "No Blinking" ;
VAL_ 563 Trip2_Blink 1 "Blinking" 0 "No Blinking" ;
VAL_ 563 Reset 7 "Reserved" 6 "Reserved" 5 "Reserved" 4 "Reserved" 3 "Clear Service Icon" 2 "Reset Trip 2" 1 "Reset Trip1" 0 "Default" ;
VAL_ 563 Odo_Reset 1 "Enabled" 0 "Disabled" ;
VAL_ 563 Service_Blink 1 "Blinking" 0 "No Blinking" ;
VAL_ 563 Hibernation 2 "Blink" 1 "Enabled" 0 "Disabled" ;
VAL_ 563 SpeedMode 3 "Rush" 2 "Ride" 1 "Eco" 0 "Default" ;
VAL_ 563 ParkBlink 1 "Blinking" 0 "No Blinking" ;
VAL_ 563 Am_Pm 1 "pm" 0 "am" ;
VAL_ 563 Mode_Blink 1 "Blinking" 0 "No Blinking" ;
VAL_ 563 SOC_Blink 1 "Blinking" 0 "No Blinking" ;
VAL_ 563 Speed_Blink 1 "Blinking" 0 "No Blinking" ;
VAL_ 332 STA_TripStatus 1 "Trip2" 0 "Trip1" ;
VAL_ 332 Reserved_2 1 "Pressed" 0 "Not  Pressed" ;
VAL_ 332 STA_Set_SwitchStatus 1 "Pressed" 0 "Not  Pressed" ;
VAL_ 332 Reserved_1 1 "Pressed" 0 "Not  Pressed" ;
VAL_ 330 STA_StatusofChargerCOMError 1 "Error" 0 "Normal" ;
VAL_ 330 STA_StatusofChargerBatError 1 "Error" 0 "Normal" ;
VAL_ 330 STA_StatsofchargerInputError 1 "Error" 0 "Normal" ;
VAL_ 330 STA_StatusofChargerTempError 1 "Error" 0 "Normal" ;
VAL_ 330 STA_StatusChargerHWError 1 "Error" 0 "Normal" ;
VAL_ 70 FLT_System_Dig_init_FaultCode 30 "FaultBitReadAFEHistoryFaultData" 29 "FAULTBIT_READ_AFE_LIFE_TIME_DATA" 28 "FAULT_BIT_INT_FLASH_WRITE_FAILED" 27 "FAULT_BIT_INT_FLASH_READ_FAILED" 26 "AULT_BIT_ADC_READ" 25 "FAULT_BIT_AFE_READ " 24 "FAULT_BIT_POST_OS_INIT_FAILED" 23 "FAULT_BIT_OS_CREATE_INTRPTS" 22 "FAULT_BIT_OS_CREATE_TASK" 21 "FAULT_BIT_OS_CREATE_QUEUE" 20 "FAULT_BIT_OS_CREATE_SEMPR" 19 "FAULT_BIT_CAN_TX" 18 "FAULT_BIT_INTERNAL_FLASH_INIT" 17 "FAULT_BIT_I2C_CRC_ERROR" 16 "FAULT_BIT_I2C_RX_ERROR" 15 "FAULT_BIT_I2C_TX_ERROR" 14 "FAULT_BIT_I2C_INIT" 13 "FAULT_BIT_ADC_INIT" 12 "FAULT_BIT_TIMER_FTM1" 11 "FAULT_BIT_TIMER_FTM0" 10 "FAULT_BIT_CAN_INIT_1" 9 "FAULT_BIT_GPIO_INIT" 8 "FAULT_BIT_CLOCK_UPDATE" 7 "FAULT_BIT_BOOT_CLOCK_INIT" 6 "FAULT_BIT_RESET_SOFT" 5 "FAULT_BIT_RESET_NRST_EXT" 4 "FAULT_BIT_RESET_ACK_ERR" 3 "FAULT_BIT_RESET_LV_DETECT" 2 "FAULT_BIT_RESET_SJTAG" 1 "FAULT_BIT_RESET_POWER_ON" 0 "FAULT_BIT_RESET_WDG" ;
VAL_ 66 WAR_BMS_State 6 "BMS_Calibration" 5 "BMS_Critical_Fault" 4 "BMS_Charging_Fault" 3 "BMS_Discharging_Fault" 2 "BMS_Charging" 1 "BMS_Discharging" 0 "Idle" ;
VAL_ 66 WAR_Batt_DFET_Temp_Warning 2 "FET_UNDER_TEMP" 1 "FET_OVER_TEMP" 0 "NO_FET_TEMP_FAULT" ;
VAL_ 66 WAR_Batt_CellVoltage_Warning 2 "UNDER_VOLTAGE_FAULT" 1 "OVER_VOLTAGE_FAULT" 0 "NO_VOLTAGE_FAULT" ;
VAL_ 66 WAR_Batt_CFET_Temp_Warning 2 "CHARG_UNDER_TEMP_FAULT" 1 "CHARG_OVER_TEMP_FAULT" 0 "NO_CHG_TEMP_FAULT" ;
VAL_ 66 WAR_Batt_Temp_Warning 4 "CHARGING_UNDER_TEMP_FAULT" 3 "DISCHARGING_UNDER_TEMPE_FAULT" 2 "CHARGING_OVER_TEMP_FAULT" 1 "DISCHARGING_OVER_TEMPE_FAULT" 0 "NO_TEMP_FAULT" ;
VAL_ 66 WAR_Batt_OverCurrent_Warning 3 "RESERVED" 2 " CHARGING_OVER_CURRENT_FAULT" 1 "DISCHARGING_OVER_CURRENT_FAULT" 0 "NO_CURRENT_FAULT" ;
VAL_ 324 Error_Actions 11 "High Battery Voltage V>100" 12 "Low Battery Voltage V<28" 13 "Over Voltage V>62" 14 "Under Voltage V<32" 15 "5V Failure" 16 "12V Failure" 17 "Sensor Calibration Error V&I" 18 "Current Sensor Fault" 21 "Over Current" 24 "Contactor Bridge Fault" 25 "Contactor  Welded" 26 "Corrupted Application Parameters" 31 "Throttle Pedal Cal Error" 33 "Throttle 1 High Voltage" 41 "Controller over temperature" 32 "Encoder Fault" 34 "Throttle 1 Low Voltage" 36 "Charging of capacitors failed " 42 "Motor over temperature" 43 "Controller temperature sensor" 44 "Motor temperature sensor" 45 "Corrupted V&I sensor calibration" 46 "Corrupted throttle calibration" 47 "Corrupted Comm parameters \r" 48 "Corrupted Persis Para" 49 "Corrupted positionsensor cal" 53 "Throttle 2 High Voltage" 54 "Throttle 1 Low Voltage" 56 "Parameter limitation" 66 "Contactor coil overcurrent" 85 "Throttle channel mismatch " 90 "Controller logicsupply error " 92 "Max. speed exceeded " 96 "Application parameters fault" 97 "Motor control error " 51 "High controller temperature " 52 "High motor temperature " 82 "Throttle SRO" 83 "Motor stalled " 93 "Kill switch SRO" 94 "Kill switch Off" ;
VAL_ 324 Error_Code_4 248 "MCU detect connection batt chgr" 247 "MCU detect faulty charger signal" 243 "NV-RAM Version" 240 "Unsupported hardware Version" 239 "Entry conditions Park not valid" 237 "BMS Status 1 CAN message Timeout" 236 "Ext contactor open Run Time" 235 "Analog GND 2 short" 234 "Analog GND 1 short" 233 "Rolling_Cnt_Error_MCU" 103 "Supply fault 12V In" 102 "Supply 5V 2nd Throttle Channel" 101 "Supply 5v first Throttle Channel" 100 "Overvoltage or Overspeed" 95 "Bridge off speed Limit" 71 "Contactor Checks" 59 "Internal error_Bridge Diff" 39 "HW overvoltage Protection" 29 "Controller Internal Error" 94 "Kill switch Off" 93 "Kill switch SRO" 83 "Motor stalled " 82 "Throttle SRO" 52 "High motor temperature " 51 "High controller temperature " 97 "Motor control error " 96 "Application parameters fault" 92 "Max. speed exceeded " 90 "Controller logicsupply error " 85 "Throttle channel mismatch " 66 "Contactor coil overcurrent" 56 "Parameter limitation" 54 "Throttle 2 Low Voltage" 53 "Throttle 2 High Voltage" 49 "Corrupted positionsensor cal" 48 "Corrupted Persis Para" 47 "Corrupted Comm parameters \r" 46 "Corrupted throttle calibration" 45 "Corrupted V&I sensor calibration" 44 "Motor temperature sensor" 43 "Bad Controller temp sensor" 42 "Motor over temperature" 36 "Charging of capacitors failed " 34 "Throttle 1 Low Voltage" 32 "Encoder Fault" 41 "Controller over temperature" 33 "Throttle 1 High Voltage" 31 "Throttle Pedal Cal Error" 26 "Corrupted Application Parameters" 25 "Contactor  Welded" 24 "Contactor Bridge Fault" 21 "Over Current" 18 "Current Sensor Fault" 17 "Sensor Calibration Error V&I" 16 "12V Failure" 15 "5V Failure" 14 "Under Voltage V<32" 13 "Over Voltage V>62" 12 "Low Battery Voltage V<28" 11 "High Battery Voltage V>100" ;
VAL_ 324 Error_Code_3 248 "MCU detect connection batt chgr" 247 "MCU detect faulty charger signal" 243 "NV-RAM Version" 240 "Unsupported hardware Version" 239 "Entry conditions Park not valid" 237 "BMS Status 1 CAN message Timeout" 236 "Ext contactor open Run Time" 235 "Analog GND 2 short" 234 "Analog GND 1 short" 233 "Rolling_Cnt_Error_MCU" 103 "Supply fault 12V In" 102 "Supply 5V 2nd Throttle Channel" 101 "Supply 5v first Throttle Channel" 100 "Overvoltage or Overspeed" 95 "Bridge off speed Limit" 71 "Contactor Checks" 59 "Internal error_Bridge Diff" 39 "HW overvoltage Protection" 29 "Controller Internal Error" 94 "Kill switch Off" 93 "Kill switch SRO" 83 "Motor stalled " 82 "Throttle SRO" 52 "High motor temperature " 51 "High controller temperature " 97 "Motor control error " 96 "Application parameters fault" 92 "Max. speed exceeded " 90 "Controller logicsupply error " 85 "Throttle channel mismatch " 66 "Contactor coil overcurrent" 56 "Parameter limitation" 54 "Throttle 2 Low Voltage" 53 "Throttle 2 High Voltage" 49 "Corrupted positionsensor cal" 48 "Corrupted Persis Para" 47 "Corrupted Comm parameters \r" 46 "Corrupted throttle calibration" 45 "Corrupted V&I sensor calibration" 44 "Motor temperature sensor" 43 "Bad Controller temp sensor" 42 "Motor over temperature" 36 "Charging of capacitors failed " 34 "Throttle 1 Low Voltage" 32 "Encoder Fault" 41 "Controller over temperature" 33 "Throttle 1 High Voltage" 31 "Throttle Pedal Cal Error" 26 "Corrupted Application Parameters" 25 "Contactor  Welded" 24 "Contactor Bridge Fault" 21 "Over Current" 18 "Current Sensor Fault" 17 "Sensor Calibration Error V&I" 16 "12V Failure" 15 "5V Failure" 14 "Under Voltage V<32" 13 "Over Voltage V>62" 12 "Low Battery Voltage V<28" 11 "High Battery Voltage V>100" ;
VAL_ 324 Error_Code_2 248 "MCU detect connection batt chgr" 247 "MCU detect faulty charger signal" 243 "NV-RAM Version" 240 "Unsupported hardware Version" 239 "Entry conditions Park not valid" 237 "BMS Status 1 CAN message Timeout" 236 "Ext contactor open Run Time" 235 "Analog GND 2 short" 234 "Analog GND 1 short" 233 "Rolling_Cnt_Error_MCU" 103 "Supply fault 12V In" 102 "Supply 5V 2nd Throttle Channel" 101 "Supply 5v first Throttle Channel" 100 "Overvoltage or Overspeed" 95 "Bridge off speed Limit" 71 "Contactor Checks" 59 "Internal error_Bridge Diff" 39 "HW overvoltage Protection" 29 "Controller Internal Error" 94 "Kill switch Off" 93 "Kill switch SRO" 83 "Motor stalled " 82 "Throttle SRO" 52 "High motor temperature " 51 "High controller temperature " 97 "Motor control error " 96 "Application parameters fault" 92 "Max. speed exceeded " 90 "Controller logicsupply error " 85 "Throttle channel mismatch " 66 "Contactor coil overcurrent" 56 "Parameter limitation" 54 "Throttle 2 Low Voltage" 53 "Throttle 2 High Voltage" 49 "Corrupted positionsensor cal" 48 "Corrupted Persis Para" 47 "Corrupted Comm parameters \r" 46 "Corrupted throttle calibration" 45 "Corrupted V&I sensor calibration" 44 "Motor temperature sensor" 43 "Bad Controller temp sensor" 42 "Motor over temperature" 36 "Charging of capacitors failed " 34 "Throttle 1 Low Voltage" 32 "Encoder Fault" 41 "Controller over temperature" 33 "Throttle 1 High Voltage" 31 "Throttle Pedal Cal Error" 26 "Corrupted Application Parameters" 25 "Contactor  Welded" 24 "Contactor Bridge Fault" 21 "Over Current" 18 "Current Sensor Fault" 17 "Sensor Calibration Error V&I" 16 "12V Failure" 15 "5V Failure" 14 "Under Voltage V<32" 13 "Over Voltage V>62" 12 "Low Battery Voltage V<28" 11 "High Battery Voltage V>100" ;
VAL_ 324 Error_Code_1 248 "MCU detect connection batt chgr" 247 "MCU detect faulty charger signal" 243 "NV-RAM Version" 240 "Unsupported hardware Version" 239 "Entry conditions Park not valid" 237 "BMS Status 1 CAN message Timeout" 236 "Ext contactor open Run Time" 235 "Analog GND 2 short" 234 "Analog GND 1 short" 233 "Rolling_Cnt_Error_MCU" 103 "Supply fault 12V In" 102 "Supply 5V 2nd Throttle Channel" 101 "Supply 5v first Throttle Channel" 100 "Overvoltage or Overspeed" 95 "Bridge off speed Limit" 71 "Contactor Checks" 59 "Internal error_Bridge Diff" 39 "HW overvoltage Protection" 29 "Controller Internal Error" 94 "Kill switch Off" 93 "Kill switch SRO" 83 "Motor stalled " 82 "Throttle SRO" 52 "High motor temperature " 51 "High controller temperature " 97 "Motor control error " 96 "Application parameters fault" 92 "Max. speed exceeded " 90 "Controller logicsupply error " 85 "Throttle channel mismatch " 66 "Contactor coil overcurrent" 56 "Parameter limitation" 54 "Throttle 2 Low Voltage" 53 "Throttle 2 High Voltage" 49 "Corrupted positionsensor cal" 48 "Corrupted Persis Para" 47 "Corrupted Comm parameters \r" 46 "Corrupted throttle calibration" 45 "Corrupted V&I sensor calibration" 44 "Motor temperature sensor" 43 "Bad Controller temp sensor" 42 "Motor over temperature" 36 "Charging of capacitors failed " 34 "Throttle 1 Low Voltage" 32 "Encoder Fault" 41 "Controller over temperature" 33 "Throttle 1 High Voltage" 31 "Throttle Pedal Cal Error" 26 "Corrupted Application Parameters" 25 "Contactor  Welded" 24 "Contactor Bridge Fault" 21 "Over Current" 18 "Current Sensor Fault" 17 "Sensor Calibration Error V&I" 16 "12V Failure" 15 "5V Failure" 14 "Under Voltage V<32" 13 "Over Voltage V>62" 12 "Low Battery Voltage V<28" 11 "High Battery Voltage V>100" ;
VAL_ 324 Error_Code_0 248 "MCU detect connection batt chgr" 247 "MCU detect faulty charger signal" 243 "NV-RAM Version" 240 "Unsupported hardware Version" 239 "Entry conditions Park not valid" 237 "BMS Status 1 CAN message Timeout" 236 "Ext contactor open Run Time" 235 "Analog GND 2 short" 234 "Analog GND 1 short" 233 "Rolling_Cnt_Error_MCU" 103 "Supply fault 12V In" 102 "Supply 5V 2nd Throttle Channel" 101 "Supply 5v first Throttle Channel" 100 "Overvoltage or Overspeed" 95 "Bridge off speed Limit" 71 "Contactor Checks" 59 "Internal error_Bridge Diff" 39 "HW overvoltage Protection" 29 "Controller Internal Error" 94 "Kill switch Off" 93 "Kill switch SRO" 83 "Motor stalled " 82 "Throttle SRO" 52 "High motor temperature " 51 "High controller temperature " 97 "Motor control error " 96 "Application parameters fault" 92 "Max. speed exceeded " 90 "Controller logicsupply error " 85 "Throttle channel mismatch " 66 "Contactor coil overcurrent" 56 "Parameter limitation" 54 "Throttle 2 Low Voltage" 53 "Throttle 2 High Voltage" 49 "Corrupted positionsensor cal" 48 "Corrupted Persis Para" 47 "Corrupted Comm parameters \r" 46 "Corrupted throttle calibration" 45 "Corrupted V&I sensor calibration" 44 "Motor temperature sensor" 43 "Bad Controller temp sensor" 42 "Motor over temperature" 36 "Charging of capacitors failed " 34 "Throttle 1 Low Voltage" 32 "Encoder Fault" 41 "Controller over temperature" 33 "Throttle 1 High Voltage" 31 "Throttle Pedal Cal Error" 26 "Corrupted Application Parameters" 25 "Contactor  Welded" 24 "Contactor Bridge Fault" 21 "Over Current" 18 "Current Sensor Fault" 17 "Sensor Calibration Error V&I" 16 "12V Failure" 15 "5V Failure" 14 "Under Voltage V<32" 13 "Over Voltage V>62" 12 "Low Battery Voltage V<28" 11 "High Battery Voltage V>100" ;
